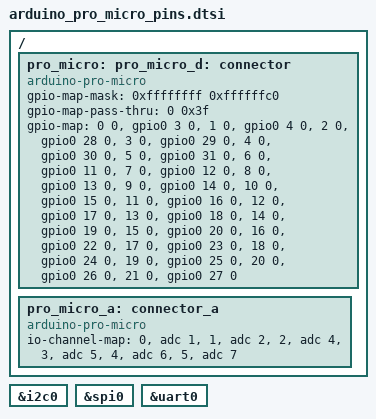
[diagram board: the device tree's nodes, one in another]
/ {
  pro_micro: connector {
    compatible = "arduino-pro-micro";
    #gpio-cells = <2>;
    gpio-map-mask = <0xffffffff 0xffffffc0>;
		gpio-map-pass-thru = <0 0x3f>;
		gpio-map =  <0 0 &gpio0 3 0>,	/* A0 */
			          <1 0 &gpio0 4 0>,	/* A1 */
			          <2 0 &gpio0 28 0>,	/* A2 */
			          <3 0 &gpio0 29 0>,	/* A3 */
			          <4 0 &gpio0 30 0>,	/* A4 */
			          <5 0 &gpio0 31 0>,	/* A5 */
			          <6 0 &gpio0 11 0>,	/* D0 */
			          <7 0 &gpio0 12 0>,	/* D1 */
			          <8 0 &gpio0 13 0>,	/* D2 */
			          <9 0 &gpio0 14 0>,	/* D3 */
			          <10 0 &gpio0 15 0>,	/* D4 */
			          <11 0 &gpio0 16 0>,	/* D5 */
			          <12 0 &gpio0 17 0>,	/* D6 */
			          <13 0 &gpio0 18 0>,	/* D7 */
			          <14 0 &gpio0 19 0>,	/* D8 */
			          <15 0 &gpio0 20 0>,	/* D9 */
			          <16 0 &gpio0 22 0>,	/* D10 */
			          <17 0 &gpio0 23 0>,	/* D11 */
			          <18 0 &gpio0 24 0>,	/* D12 */
			          <19 0 &gpio0 25 0>,	/* D13 */
			          <20 0 &gpio0 26 0>,	/* D14 */
			          <21 0 &gpio0 27 0>;	/* D15 */
  };

  pro_micro_a: connector_a {
		compatible = "arduino-pro-micro";
		#io-channel-cells = <1>;
		io-channel-map = <0 &adc 1>,	/* A0 = P0.3 = AIN1 */
				 <1 &adc 2>,	/* A1 = P0.4 = AIN2 */
				 <2 &adc 4>,	/* A2 = P0.28 = AIN4 */
				 <3 &adc 5>,	/* A3 = P0.29 = AIN5 */
				 <4 &adc 6>,	/* A4 = P0.30 = AIN6 */
				 <5 &adc 7>;	/* A5 = P0.31 = AIN7 */
	};
};

pro_micro_d: &pro_micro {};
pro_micro_i2c: &i2c0 {};
pro_micro_spi: &spi0 {};
pro_micro_serial: &uart0 {};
